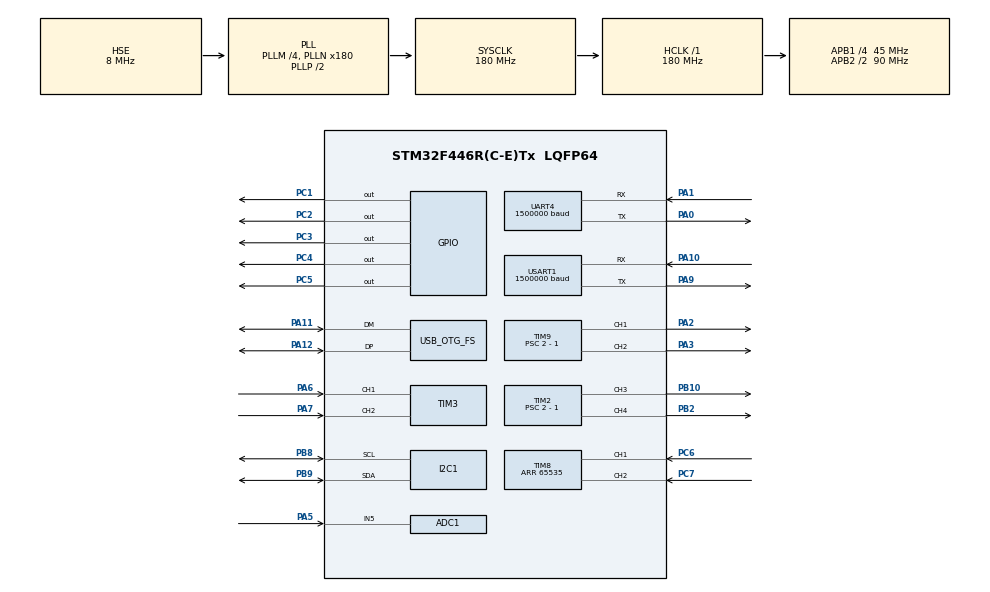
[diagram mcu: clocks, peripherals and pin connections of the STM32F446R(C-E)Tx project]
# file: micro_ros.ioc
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ADC1.Channel-1\#ChannelRegularConversion=ADC_CHANNEL_5
ADC1.NbrOfConversionFlag=1
ADC1.Rank-1\#ChannelRegularConversion=1
ADC1.SamplingTime-1\#ChannelRegularConversion=ADC_SAMPLETIME_3CYCLES
ADC1.master=1
Dma.Request0=USART1_RX
Dma.Request1=USART1_TX
Dma.USART1_RX.0.Direction=DMA_PERIPH_TO_MEMORY
Dma.USART1_RX.0.FIFOMode=DMA_FIFOMODE_DISABLE
Dma.USART1_RX.0.Instance=DMA2_Stream2
Dma.USART1_RX.0.MemDataAlignment=DMA_MDATAALIGN_BYTE
Dma.USART1_RX.0.MemInc=DMA_MINC_ENABLE
Dma.USART1_RX.0.Mode=DMA_CIRCULAR
Dma.USART1_RX.0.PeriphDataAlignment=DMA_PDATAALIGN_BYTE
Dma.USART1_RX.0.PeriphInc=DMA_PINC_DISABLE
Dma.USART1_RX.0.Priority=DMA_PRIORITY_VERY_HIGH
Dma.USART1_TX.1.Direction=DMA_MEMORY_TO_PERIPH
Dma.USART1_TX.1.FIFOMode=DMA_FIFOMODE_DISABLE
Dma.USART1_TX.1.Instance=DMA2_Stream7
Dma.USART1_TX.1.MemDataAlignment=DMA_MDATAALIGN_BYTE
Dma.USART1_TX.1.MemInc=DMA_MINC_ENABLE
Dma.USART1_TX.1.Mode=DMA_NORMAL
Dma.USART1_TX.1.PeriphDataAlignment=DMA_PDATAALIGN_BYTE
Dma.USART1_TX.1.PeriphInc=DMA_PINC_DISABLE
Dma.USART1_TX.1.Priority=DMA_PRIORITY_VERY_HIGH
FREERTOS.Tasks01=InitTask,55,1024,StartInitTask,As weak,NULL,Dynamic,NULL,NULL;DebugTask,8,256,StartDebugTask,As weak,NULL,Dynamic,NULL,NULL;IMUTask,24,512,StartIMUTask,As weak,NULL,Dynamic,NULL,NULL;BatteryTask,24,512,StartBatteryTask,As weak,NULL,Dynamic,NULL,NULL;TimeSyncTask,40,256,StartTimeSyncTask,As weak,NULL,Dynamic,NULL,NULL;DiffDriveTask,40,512,StartDiffDriveTask,As weak,NULL,Dynamic,NULL,NULL;VelocityTask,24,512,StartVelocityTask,As weak,NULL,Dynamic,NULL,NULL;BatteryLedTask,24,256,StartBatteryLedTask,As weak,NULL,Dynamic,NULL,NULL;IWDGTask,55,128,StartIWDGTask,As weak,NULL,Dynamic,NULL,NULL
FREERTOS.configENABLE_FPU=1
FREERTOS.configGENERATE_RUN_TIME_STATS=1
FREERTOS.configMAX_TASK_NAME_LEN=32
FREERTOS.configRECORD_STACK_HIGH_ADDRESS=1
FREERTOS.configTOTAL_HEAP_SIZE=25000
FREERTOS.configUSE_NEWLIB_REENTRANT=1
FREERTOS.configUSE_STATS_FORMATTING_FUNCTIONS=1
I2C1.I2C_Mode=I2C_Fast
IWDG.Prescaler=IWDG_PRESCALER_64
IWDG.Reload=799
Mcu.Family=STM32F4
Mcu.Name=STM32F446R(C-E)Tx
Mcu.Package=LQFP64
NVIC.DMA2_Stream2_IRQn=true\:5\:0\:false\:false\:true\:true\:false\:true\:true
NVIC.DMA2_Stream7_IRQn=true\:5\:0\:false\:false\:true\:true\:false\:true\:true
NVIC.OTG_FS_IRQn=true\:5\:0\:false\:false\:true\:true\:false\:true\:true
NVIC.PriorityGroup=NVIC_PRIORITYGROUP_4
NVIC.TIM8_TRG_COM_TIM14_IRQn=true\:5\:0\:false\:false\:true\:false\:false\:true\:true
NVIC.TimeBase=TIM8_TRG_COM_TIM14_IRQn
NVIC.TimeBaseIP=TIM14
NVIC.USART1_IRQn=true\:5\:0\:false\:false\:true\:true\:true\:true\:true
PA0-WKUP.Mode=Asynchronous
PA0-WKUP.Signal=UART4_TX
PA1.Mode=Asynchronous
PA1.Signal=UART4_RX
PA10.Mode=Asynchronous
PA10.Signal=USART1_RX
PA11.Mode=Device_Only
PA11.Signal=USB_OTG_FS_DM
PA12.Mode=Device_Only
PA12.Signal=USB_OTG_FS_DP
PA13.Mode=Trace_Asynchronous_SW
PA13.Signal=SYS_JTMS-SWDIO
PA14.Mode=Trace_Asynchronous_SW
PA14.Signal=SYS_JTCK-SWCLK
PA2.Signal=S_TIM9_CH1
PA3.Signal=S_TIM9_CH2
PA5.Signal=ADCx_IN5
PA6.Signal=S_TIM3_CH1
PA7.Signal=S_TIM3_CH2
PA9.Mode=Asynchronous
PA9.Signal=USART1_TX
PB10.Signal=S_TIM2_CH3
PB2.Signal=S_TIM2_CH4
PB3.Mode=Trace_Asynchronous_SW
PB3.Signal=SYS_JTDO-SWO
PB8.Mode=I2C
PB8.Signal=I2C1_SCL
PB9.Mode=I2C
PB9.Signal=I2C1_SDA
PC1.Signal=GPIO_Output
PC2.Signal=GPIO_Output
PC3.Signal=GPIO_Output
PC4.Signal=GPIO_Output
PC5.Signal=GPIO_Output
PC6.Signal=S_TIM8_CH1
PC7.Signal=S_TIM8_CH2
PH0-OSC_IN.Mode=HSE-External-Oscillator
PH0-OSC_IN.Signal=RCC_OSC_IN
PH1-OSC_OUT.Mode=HSE-External-Oscillator
PH1-OSC_OUT.Signal=RCC_OSC_OUT
ProjectManager.HeapSize=0x200
ProjectManager.StackSize=0x400
ProjectManager.TargetToolchain=STM32CubeIDE
RCC.AHBFreq_Value=180000000
RCC.APB1CLKDivider=RCC_HCLK_DIV4
RCC.APB1Freq_Value=45000000
RCC.APB1TimFreq_Value=90000000
RCC.APB2CLKDivider=RCC_HCLK_DIV2
RCC.APB2Freq_Value=90000000
RCC.APB2TimFreq_Value=180000000
RCC.CortexFreq_Value=180000000
RCC.HCLKFreq_Value=180000000
RCC.HSE_VALUE=8000000
RCC.PLLM=4
RCC.PLLN=180
RCC.PLLSAIM=7
RCC.PLLSAIN=168
RCC.PLLSAIP=RCC_PLLSAIP_DIV4
RCC.PLLSourceVirtual=RCC_PLLSOURCE_HSE
RCC.SYSCLKFreq_VALUE=180000000
RCC.SYSCLKSource=RCC_SYSCLKSOURCE_PLLCLK
RCC.USBCLockSelection=RCC_CLK48CLKSOURCE_PLLSAIP
RCC.USBFreq_Value=48000000.00000001
RCC.VCOOutputFreq_Value=360000000
SH.ADCx_IN5.0=ADC1_IN5,IN5
SH.S_TIM2_CH3.0=TIM2_CH3,PWM Generation3 CH3
SH.S_TIM2_CH4.0=TIM2_CH4,PWM Generation4 CH4
SH.S_TIM3_CH1.0=TIM3_CH1,Encoder_Interface
SH.S_TIM3_CH2.0=TIM3_CH2,Encoder_Interface
SH.S_TIM8_CH1.0=TIM8_CH1,Encoder_Interface
SH.S_TIM8_CH2.0=TIM8_CH2,Encoder_Interface
SH.S_TIM9_CH1.0=TIM9_CH1,PWM Generation1 CH1
SH.S_TIM9_CH2.0=TIM9_CH2,PWM Generation2 CH2
TIM2.Channel-PWM\ Generation3\ CH3=TIM_CHANNEL_3
TIM2.Channel-PWM\ Generation4\ CH4=TIM_CHANNEL_4
TIM2.Period=2250 - 1
TIM2.Prescaler=2 - 1
TIM3.AutoReloadPreload=TIM_AUTORELOAD_PRELOAD_ENABLE
TIM3.EncoderMode=TIM_ENCODERMODE_TI12
TIM8.CounterMode=TIM_COUNTERMODE_UP
TIM8.EncoderMode=TIM_ENCODERMODE_TI12
TIM8.Period=65535
TIM9.Channel-PWM\ Generation1\ CH1=TIM_CHANNEL_1
TIM9.Channel-PWM\ Generation2\ CH2=TIM_CHANNEL_2
TIM9.Period=2250 - 1
TIM9.Prescaler=2 - 1
UART4.BaudRate=1500000
UART4.VirtualMode=Asynchronous
USART1.BaudRate=1500000
USART1.VirtualMode=VM_ASYNC
USB_DEVICE.CLASS_NAME_FS=CDC
USB_DEVICE.VirtualMode-CDC_FS=Cdc
USB_DEVICE.VirtualModeFS=Cdc_FS
USB_OTG_FS.VirtualMode=Device_Only
VP_FREERTOS_VS_CMSIS_V2.Mode=CMSIS_V2
VP_IWDG_VS_IWDG.Mode=IWDG_Activate
VP_SYS_VS_tim14.Mode=TIM14
VP_TIM2_VS_ClockSourceINT.Mode=Internal
VP_TIM9_VS_ClockSourceINT.Mode=Internal
VP_USB_DEVICE_VS_USB_DEVICE_CDC_FS.Mode=CDC_FS
board=custom

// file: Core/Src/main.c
/* USER CODE BEGIN Header */
/**
 ******************************************************************************
 * @file           : main.c
 * @brief          : Main program body
 ******************************************************************************
 * @attention
 *
 * Copyright (c) 2025 STMicroelectronics.
 * All rights reserved.
 *
 * This software is licensed under terms that can be found in the LICENSE file
 * in the root directory of this software component.
 * If no LICENSE file comes with this software, it is provided AS-IS.
 *
 ******************************************************************************
 */
/* USER CODE END Header */
#include "main.h"
#include "cmsis_os.h"
#include "adc.h"
#include "dma.h"
#include "i2c.h"
#include "iwdg.h"
#include "tim.h"
#include "usart.h"
#include "usb_device.h"
#include "gpio.h"

void SystemClock_Config(void);
void MX_FREERTOS_Init(void);

int main(void)
{

  /* MCU Configuration--------------------------------------------------------*/

  /* Reset of all peripherals, Initializes the Flash interface and the Systick. */
  HAL_Init();

  /* Configure the system clock */
  SystemClock_Config();

  /* Initialize all configured peripherals */
  MX_GPIO_Init();
  MX_DMA_Init();
  MX_TIM2_Init();
  MX_TIM3_Init();
  MX_TIM8_Init();
  MX_ADC1_Init();
  MX_I2C1_Init();
  MX_TIM9_Init();
  MX_UART4_Init();
  MX_USART1_UART_Init();
  MX_IWDG_Init();
  /* USER CODE BEGIN 2 */
  MX_USB_DEVICE_Init();
  /* USER CODE END 2 */

  /* Init scheduler */
  osKernelInitialize();  /* Call init function for freertos objects (in cmsis_os2.c) */
  MX_FREERTOS_Init();

  /* Start scheduler */
  osKernelStart();

  /* We should never get here as control is now taken by the scheduler */

  /* Infinite loop */
    while (1) {

    }
}

void SystemClock_Config(void)
{
  RCC_OscInitTypeDef RCC_OscInitStruct = {0};
  RCC_ClkInitTypeDef RCC_ClkInitStruct = {0};

  /** Configure the main internal regulator output voltage
  */
  __HAL_RCC_PWR_CLK_ENABLE();
  __HAL_PWR_VOLTAGESCALING_CONFIG(PWR_REGULATOR_VOLTAGE_SCALE1);

  /** Initializes the RCC Oscillators according to the specified parameters
  * in the RCC_OscInitTypeDef structure.
  */
  RCC_OscInitStruct.OscillatorType = RCC_OSCILLATORTYPE_LSI|RCC_OSCILLATORTYPE_HSE;
  RCC_OscInitStruct.HSEState = RCC_HSE_ON;
  RCC_OscInitStruct.LSIState = RCC_LSI_ON;
  RCC_OscInitStruct.PLL.PLLState = RCC_PLL_ON;
  RCC_OscInitStruct.PLL.PLLSource = RCC_PLLSOURCE_HSE;
  RCC_OscInitStruct.PLL.PLLM = 4;
  RCC_OscInitStruct.PLL.PLLN = 180;
  RCC_OscInitStruct.PLL.PLLP = RCC_PLLP_DIV2;
  RCC_OscInitStruct.PLL.PLLQ = 2;
  RCC_OscInitStruct.PLL.PLLR = 2;
  if (HAL_RCC_OscConfig(&RCC_OscInitStruct) != HAL_OK)
  {
    Error_Handler();
  }

  /** Activate the Over-Drive mode
  */
  if (HAL_PWREx_EnableOverDrive() != HAL_OK)
  {
    Error_Handler();
  }

  /** Initializes the CPU, AHB and APB buses clocks
  */
  RCC_ClkInitStruct.ClockType = RCC_CLOCKTYPE_HCLK|RCC_CLOCKTYPE_SYSCLK
                              |RCC_CLOCKTYPE_PCLK1|RCC_CLOCKTYPE_PCLK2;
  RCC_ClkInitStruct.SYSCLKSource = RCC_SYSCLKSOURCE_PLLCLK;
  RCC_ClkInitStruct.AHBCLKDivider = RCC_SYSCLK_DIV1;
  RCC_ClkInitStruct.APB1CLKDivider = RCC_HCLK_DIV4;
  RCC_ClkInitStruct.APB2CLKDivider = RCC_HCLK_DIV2;

  if (HAL_RCC_ClockConfig(&RCC_ClkInitStruct, FLASH_LATENCY_5) != HAL_OK)
  {
    Error_Handler();
  }
}

void HAL_TIM_PeriodElapsedCallback(TIM_HandleTypeDef *htim)
{
  if (htim->Instance == TIM14)
  {
    HAL_IncTick();
  }
}

void Error_Handler(void)
{
    __disable_irq();
    while (1) {
    }
}

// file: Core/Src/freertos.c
/* USER CODE BEGIN Header */
/**
 ******************************************************************************
 * File Name          : freertos.c
 * Description        : Code for freertos applications
 ******************************************************************************
 * @attention
 *
 * Copyright (c) 2025 STMicroelectronics.
 * All rights reserved.
 *
 * This software is licensed under terms that can be found in the LICENSE file
 * in the root directory of this software component.
 * If no LICENSE file comes with this software, it is provided AS-IS.
 *
 ******************************************************************************
 */
/* USER CODE END Header */

#include "FreeRTOS.h"
#include "task.h"
#include "main.h"
#include "cmsis_os.h"

/* Definitions for InitTask */
osThreadId_t InitTaskHandle;
const osThreadAttr_t InitTask_attributes = {
  .name = "InitTask",
  .stack_size = 1024 * 4,
  .priority = (osPriority_t) osPriorityRealtime7,
};
/* Definitions for DebugTask */
osThreadId_t DebugTaskHandle;
const osThreadAttr_t DebugTask_attributes = {
  .name = "DebugTask",
  .stack_size = 256 * 4,
  .priority = (osPriority_t) osPriorityLow,
};
/* Definitions for IMUTask */
osThreadId_t IMUTaskHandle;
const osThreadAttr_t IMUTask_attributes = {
  .name = "IMUTask",
  .stack_size = 512 * 4,
  .priority = (osPriority_t) osPriorityNormal,
};
/* Definitions for BatteryTask */
osThreadId_t BatteryTaskHandle;
const osThreadAttr_t BatteryTask_attributes = {
  .name = "BatteryTask",
  .stack_size = 512 * 4,
  .priority = (osPriority_t) osPriorityNormal,
};
/* Definitions for TimeSyncTask */
osThreadId_t TimeSyncTaskHandle;
const osThreadAttr_t TimeSyncTask_attributes = {
  .name = "TimeSyncTask",
  .stack_size = 256 * 4,
  .priority = (osPriority_t) osPriorityHigh,
};
/* Definitions for DiffDriveTask */
osThreadId_t DiffDriveTaskHandle;
const osThreadAttr_t DiffDriveTask_attributes = {
  .name = "DiffDriveTask",
  .stack_size = 512 * 4,
  .priority = (osPriority_t) osPriorityHigh,
};
/* Definitions for VelocityTask */
osThreadId_t VelocityTaskHandle;
const osThreadAttr_t VelocityTask_attributes = {
  .name = "VelocityTask",
  .stack_size = 512 * 4,
  .priority = (osPriority_t) osPriorityNormal,
};
/* Definitions for BatteryLedTask */
osThreadId_t BatteryLedTaskHandle;
const osThreadAttr_t BatteryLedTask_attributes = {
  .name = "BatteryLedTask",
  .stack_size = 256 * 4,
  .priority = (osPriority_t) osPriorityNormal,
};
/* Definitions for IWDGTask */
osThreadId_t IWDGTaskHandle;
const osThreadAttr_t IWDGTask_attributes = {
  .name = "IWDGTask",
  .stack_size = 128 * 4,
  .priority = (osPriority_t) osPriorityRealtime7,
};

void StartInitTask(void *argument);
void StartDebugTask(void *argument);
void StartIMUTask(void *argument);
void StartBatteryTask(void *argument);
void StartTimeSyncTask(void *argument);
void StartDiffDriveTask(void *argument);
void StartVelocityTask(void *argument);
void StartBatteryLedTask(void *argument);
void StartIWDGTask(void *argument);

extern void MX_USB_DEVICE_Init(void);
void MX_FREERTOS_Init(void); /* (MISRA C 2004 rule 8.1) */

/* Hook prototypes */
void configureTimerForRunTimeStats(void);
unsigned long getRunTimeCounterValue(void);

/* USER CODE BEGIN 1 */
/* Functions needed when configGENERATE_RUN_TIME_STATS is on */
__weak void configureTimerForRunTimeStats(void) {
    CoreDebug->DEMCR |= CoreDebug_DEMCR_TRCENA_Msk;
    DWT->CTRL |= 1;
    DWT->CYCCNT = 0;
}

__weak unsigned long getRunTimeCounterValue(void) {
    return DWT->CYCCNT;
}
/* USER CODE END 1 */

void MX_FREERTOS_Init(void) {

  /* Create the thread(s) */
  /* creation of InitTask */
  InitTaskHandle = osThreadNew(StartInitTask, NULL, &InitTask_attributes);

  /* creation of DebugTask */
  DebugTaskHandle = osThreadNew(StartDebugTask, NULL, &DebugTask_attributes);

  /* creation of IMUTask */
  IMUTaskHandle = osThreadNew(StartIMUTask, NULL, &IMUTask_attributes);

  /* creation of BatteryTask */
  BatteryTaskHandle = osThreadNew(StartBatteryTask, NULL, &BatteryTask_attributes);

  /* creation of TimeSyncTask */
  TimeSyncTaskHandle = osThreadNew(StartTimeSyncTask, NULL, &TimeSyncTask_attributes);

  /* creation of DiffDriveTask */
  DiffDriveTaskHandle = osThreadNew(StartDiffDriveTask, NULL, &DiffDriveTask_attributes);

  /* creation of VelocityTask */
  VelocityTaskHandle = osThreadNew(StartVelocityTask, NULL, &VelocityTask_attributes);

  /* creation of BatteryLedTask */
  BatteryLedTaskHandle = osThreadNew(StartBatteryLedTask, NULL, &BatteryLedTask_attributes);

  /* creation of IWDGTask */
  IWDGTaskHandle = osThreadNew(StartIWDGTask, NULL, &IWDGTask_attributes);

}

__weak void StartInitTask(void *argument)
{
  /* init code for USB_DEVICE */
  //MX_USB_DEVICE_Init();
  /* USER CODE BEGIN StartInitTask */
  UNUSED(argument);
  /* USER CODE END StartInitTask */
}

__weak void StartDebugTask(void *argument)
{
  /* USER CODE BEGIN StartDebugTask */
  UNUSED(argument);
  /* USER CODE END StartDebugTask */
}

__weak void StartIMUTask(void *argument)
{
  /* USER CODE BEGIN StartIMUTask */
  UNUSED(argument);
  /* USER CODE END StartIMUTask */
}

__weak void StartBatteryTask(void *argument)
{
  /* USER CODE BEGIN StartBatteryTask */
  UNUSED(argument);
  /* USER CODE END StartBatteryTask */
}

__weak void StartTimeSyncTask(void *argument)
{
  /* USER CODE BEGIN StartTimeSyncTask */
  UNUSED(argument);
  /* USER CODE END StartTimeSyncTask */
}

__weak void StartDiffDriveTask(void *argument)
{
  /* USER CODE BEGIN StartDiffDriveTask */
  UNUSED(argument);
  /* USER CODE END StartDiffDriveTask */
}

__weak void StartVelocityTask(void *argument)
{
  /* USER CODE BEGIN StartVelocityTask */
  UNUSED(argument);
  /* USER CODE END StartVelocityTask */
}

__weak void StartBatteryLedTask(void *argument)
{
  /* USER CODE BEGIN StartBatteryLedTask */
  UNUSED(argument);
  /* USER CODE END StartBatteryLedTask */
}

__weak void StartIWDGTask(void *argument)
{
  /* USER CODE BEGIN StartIWDGTask */
  UNUSED(argument);
  /* USER CODE END StartIWDGTask */
}
